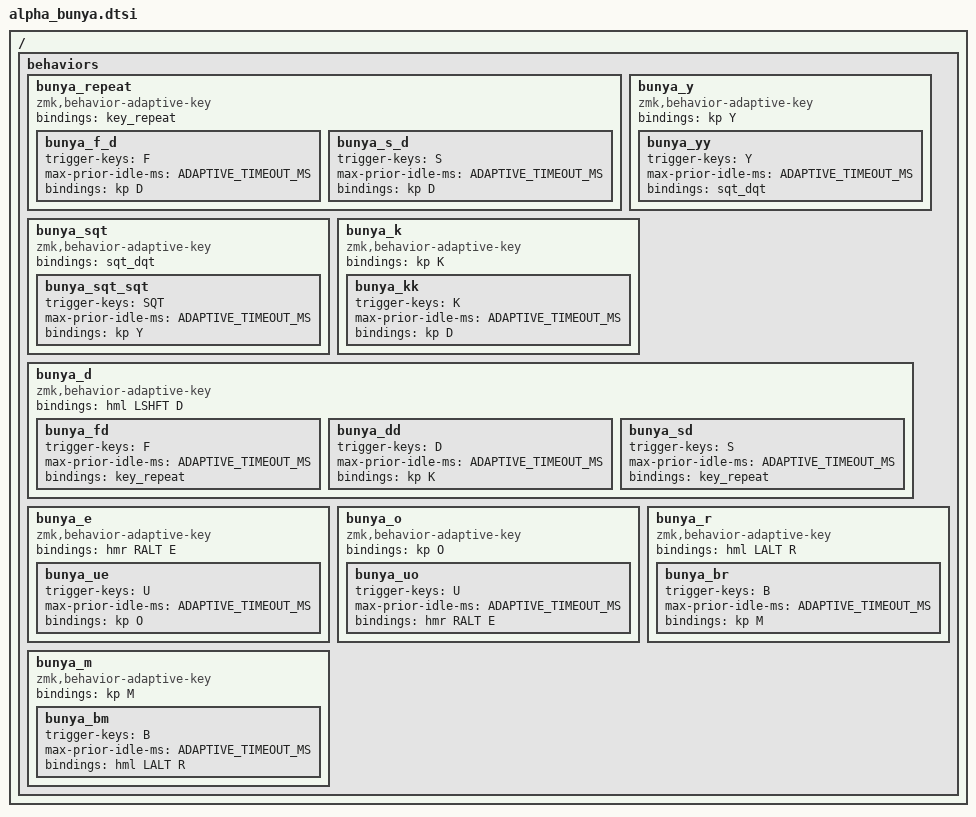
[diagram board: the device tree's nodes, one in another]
ZMK_ADAPTIVE_KEY(bunya_repeat, bindings = <&key_repeat>;
    bunya_f_d { trigger-keys = <F>; max-prior-idle-ms = <ADAPTIVE_TIMEOUT_MS>; bindings = <&kp D>; };
    bunya_s_d { trigger-keys = <S>; max-prior-idle-ms = <ADAPTIVE_TIMEOUT_MS>; bindings = <&kp D>; };
)

ZMK_ADAPTIVE_KEY(bunya_y, bindings = <&kp Y>;
    bunya_yy { trigger-keys = <Y>; max-prior-idle-ms = <ADAPTIVE_TIMEOUT_MS>; bindings = <&sqt_dqt>; };
)

ZMK_ADAPTIVE_KEY(bunya_sqt, bindings = <&sqt_dqt>;
    bunya_sqt_sqt { trigger-keys = <SQT>; max-prior-idle-ms = <ADAPTIVE_TIMEOUT_MS>; bindings = <&kp Y>; };
)

ZMK_ADAPTIVE_KEY(bunya_k, bindings = <&kp K>;
    bunya_kk { trigger-keys = <K>; max-prior-idle-ms = <ADAPTIVE_TIMEOUT_MS>; bindings = <&kp D>; };
)

ZMK_ADAPTIVE_KEY(bunya_d, bindings = <&hml LSHFT D>;
    bunya_fd { trigger-keys = <F>; max-prior-idle-ms = <ADAPTIVE_TIMEOUT_MS>; bindings = <&key_repeat>; };
    bunya_dd { trigger-keys = <D>; max-prior-idle-ms = <ADAPTIVE_TIMEOUT_MS>; bindings = <&kp K>; };
    bunya_sd { trigger-keys = <S>; max-prior-idle-ms = <ADAPTIVE_TIMEOUT_MS>; bindings = <&key_repeat>; };
)

ZMK_ADAPTIVE_KEY(bunya_e, bindings = <&hmr RALT E>;
    bunya_ue { trigger-keys = <U>; max-prior-idle-ms = <ADAPTIVE_TIMEOUT_MS>; bindings = <&kp O>; };
)

ZMK_ADAPTIVE_KEY(bunya_o, bindings = <&kp O>;
    bunya_uo { trigger-keys = <U>; max-prior-idle-ms = <ADAPTIVE_TIMEOUT_MS>; bindings = <&hmr RALT E>; };
)

ZMK_ADAPTIVE_KEY(bunya_r, bindings = <&hml LALT R>;
    bunya_br { trigger-keys = <B>; max-prior-idle-ms = <ADAPTIVE_TIMEOUT_MS>; bindings = <&kp M>; };
)

ZMK_ADAPTIVE_KEY(bunya_m, bindings = <&kp M>;
    bunya_bm { trigger-keys = <B>; max-prior-idle-ms = <ADAPTIVE_TIMEOUT_MS>; bindings = <&hml LALT R>; };
)

ZMK_BASE_LAYER(BunyaAlpha,
    &kp B      &kp L      &bunya_m   &kp G      &kp W      ,  &kp J      &kp F      &bunya_o   &kp U      &comma_excl ,
    &hml LGUI N &bunya_r  &hml LCTRL T &bunya_d &kp P      ,  &bunya_y   &hmr RSHFT H &hmr RCTRL A &bunya_e &hmr RGUI I ,
    &kp X      &kp Q      &kp V      &kp C      &kp Z      ,  &bunya_k   &bunya_repeat &bunya_sqt &minus_slash &dot_qmark ,
            LH_NONE &thumb_bspc LAYER_Nav 0  &kp S , &thumb_spc LAYER_Symbol SPACE  &num_shift LAYER_Num LSHFT RH_NONE
)
